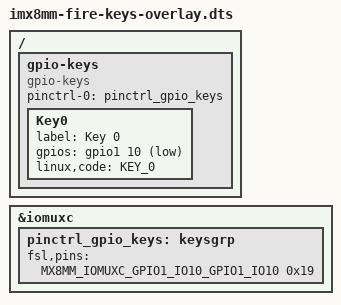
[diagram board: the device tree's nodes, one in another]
/*
 * Copyright (C) 2021 - All Rights Reserved by 
 * filename : imx8mm-fire-keys-overlay.dts
 * brief : Device Tree overlay for ebf imx8mm uart3 device
 * author : embedfire
 * date : 2021-12-01 
 * version : A001
 */

/dts-v1/;
/plugin/;

#include "../imx8mm-pinfunc.h"
#include "dt-bindings/gpio/gpio.h"
#include "dt-bindings/input/linux-event-codes.h"

/ {
	fragment@0 {
		target-path = "/";
		__overlay__ {
			gpio-keys {
				compatible = "gpio-keys";
				pinctrl-names = "default";
				pinctrl-0 = <&pinctrl_gpio_keys>;

				Key0 {
					label = "Key 0";
					gpios = <&gpio1 10 GPIO_ACTIVE_LOW>;
					linux,code=<KEY_0>;                  
				};

			};
		};
	};
	
	fragment@1 {
		target= <&iomuxc>;
		__overlay__{
			pinctrl_gpio_keys: keysgrp{
				fsl,pins = <
                        MX8MM_IOMUXC_GPIO1_IO10_GPIO1_IO10		0x19
				>;
			};
		};
	};
};
